# STM32H563 register map
File version: 1.6
CPU: CM33 r0p0, little endian, MPU, FPU, 4 interrupt priority bits
Registers are 32-bit, read-write, reset 0x0 unless marked. A register's access mark holds for its fields unless they carry their own. Offsets are from the block's base; [hi:lo] are bit positions; {n}, {i} and the like mark numbered series; 'fields as' and 'values as' point back to an identical list.

## RAMCFG — RAMs configuration controller
Base 0x40026000
Same registers: SEC_RAMCFG 0x50026000
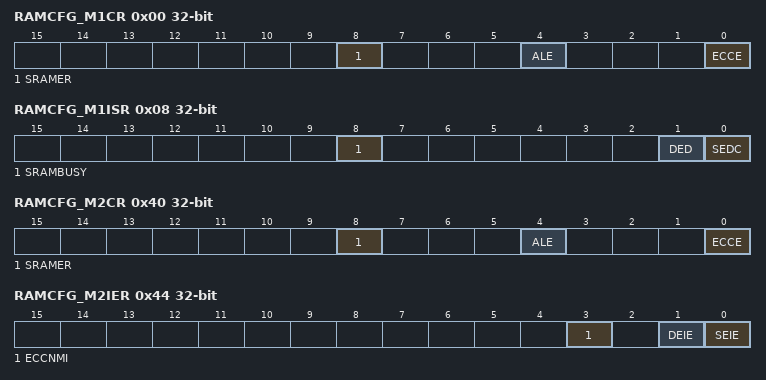
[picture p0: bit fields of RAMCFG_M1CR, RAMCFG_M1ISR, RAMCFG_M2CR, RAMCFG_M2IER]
0x00 RAMCFG_M1CR (reset mask 0xFFFFFFF0) — RAMCFG memory 1 control register
  [8] SRAMER — SRAM erase This bit can be set by software only after writing the unlock sequence in the ERASEKEY field of the RAMCFG_MxERKEYR register. Setting this bit starts the SRAM erase. This bit is automatically cleared by hardware at the end of the erase operation.
    0=No erase operation on going; 1=Erase operation on going
  [4] ALE — Address latch enable Note: This bit is reserved and must be kept at reset value in SRAM1 control register.
    0=Failing address not stored in the SRAMx ECC single/double error address registers; 1=Failing address stored in the SRAMx ECC single/double error address registers
  [0] ECCE — ECC enable. This bit reset value is defined by the user option bit configuration. When set, it can be cleared by software only after writing the unlock sequence in the RAMCFG_MxECCKEYR register. Note: This bit is reserved and must be kept at reset value in SRAM1 control register.
    0=ECC disabled; 1=ECC enabled
0x08 RAMCFG_M1ISR ro — RAMCFG memory interrupt status register
  [8] SRAMBUSY — SRAM busy with erase operation Note: Depending on the SRAM, the erase operation can be performed due to software request, system reset if the option bit is enabled, tamper detection or readout protection regression. Refer to Table 18: Internal SRAMs features.
    0=No erase operation on going; 1=Erase operation on going
  [1] DED — ECC double error detected Note: This bit is reserved and must be kept at reset value in SRAM1 interrupt status register.
    0=No double error; 1=Double error detected
  [0] SEDC — ECC single error detected and corrected Note: This bit is reserved and must be kept at reset value in SRAM1 interrupt status register.
    0=No single error; 1=Single error detected and corrected
0x28 RAMCFG_M1ERKEYR wo — RAMCFG memory 1 erase key register
  [7:0] ERASEKEY — Erase write protection key The following steps are required to unlock the write protection of the SRAMER bit in the RAMCFG_MxCR register. 1) Write 0xCA into ERASEKEY[7:0]. 2) Write 0x53 into ERASEKEY[7:0]. Note: Writing a wrong key reactivates the write protection.
0x40 RAMCFG_M2CR (reset mask 0xFFFFFFF0) — RAMCFG memory 2 control register
  fields as RAMCFG_M1CR
0x44 RAMCFG_M2IER — RAMCFG memory 2 interrupt enable register
  [3] ECCNMI — Double error NMI This bit is set by software and cleared only by a global RAMCFG reset. Note: if ECCNMI is set, the RAMCFG maskable interrupt is not generated whatever DEIE bit value.
    0=NMI not generated in case of ECC double error; 1=NMI generated in case of ECC double error
  [1] DEIE — ECC double error interrupt enable
    0=Double error interrupt disabled; 1=Double error interrupt enabled
  [0] SEIE — ECC single error interrupt enable
    0=Single error interrupt disabled; 1=Single error interrupt enabled
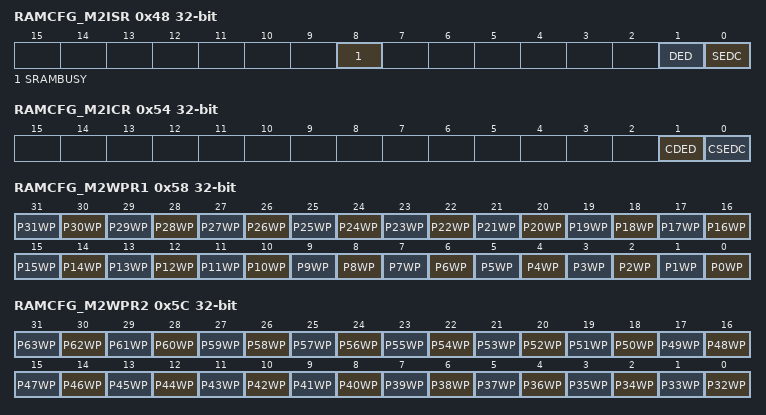
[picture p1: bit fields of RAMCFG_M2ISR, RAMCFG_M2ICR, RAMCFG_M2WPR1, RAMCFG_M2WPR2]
0x48 RAMCFG_M2ISR ro — RAMCFG memory interrupt status register
  fields as RAMCFG_M1ISR
0x4C RAMCFG_M2SEAR ro — RAMCFG memory 2 ECC single error address register
  [31:0] ESEA — ECC single error address When the ALE bit is set in the RAMCFG_MxCR register, this field is updated with the address corresponding to the ECC single error.
0x50 RAMCFG_M2DEAR ro — RAMCFG memory 2 ECC double error address register
  [31:0] EDEA — ECC double error address When the ALE bit is set in the RAMCFG_MxCR register, this field is updated with the address corresponding to the ECC double error.
0x54 RAMCFG_M2ICR — RAMCFG memory 2 interrupt clear register 2
  [1] CDED — Clear ECC double error detected Writing 1 to this flag clears the DED bit in the RAMCFG_MxISR register. Reading this flag returns the DED value.
  [0] CSEDC — Clear ECC single error detected and corrected Writing 1 to this flag clears the SEDC bit in the RAMCFG_MxISR register. Reading this flag returns the SEDC value.
0x58 RAMCFG_M2WPR1 — RAMCFG memory 2 write protection register 1
  [all] fields
    0=Write protection of SRAM2 1-Kbyte page y is disabled; 1=Write protection of SRAM2 1-Kbyte page y is enabled
  [n] P{n}WP (n=0..31) — SRAM2 1-Kbyte page y write protection These bits are set by software and cleared only by a global RAMCFG reset.
0x5C RAMCFG_M2WPR2 — RAMCFG memory 2 write protection register 2
  [all] fields
    values as the fields of RAMCFG_M2WPR1
  [n-32] P{n}WP (n=32..63) — SRAM2 1-Kbyte page y write protection These bits are set by software and cleared only by a global RAMCFG reset.
0x64 RAMCFG_M2ECCKEYR wo — RAMCFG memory 2 ECC key register
  [7:0] ECCKEY — ECC write protection key The following steps are required to unlock the write protection of the ECCE bit in the RAMCFG_MxCR register. 1) Write 0xAE into ECCKEY[7:0]. 2) Write 0x75 into ECCKEY[7:0]. Note: Writing a wrong key reactivates the write protection.
0x68 RAMCFG_M2ERKEYR wo — RAMCFG memory 2 erase key register
  fields as RAMCFG_M1ERKEYR
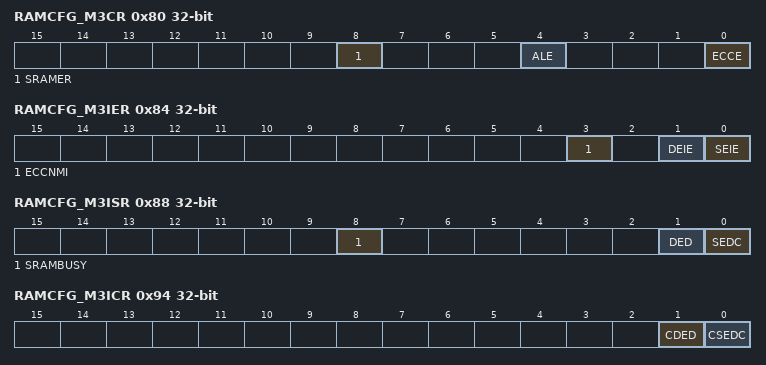
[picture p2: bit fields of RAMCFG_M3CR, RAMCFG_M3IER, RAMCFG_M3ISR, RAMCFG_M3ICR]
0x80 RAMCFG_M3CR (reset mask 0xFFFFFFF0) — RAMCFG memory 3 control register
  fields as RAMCFG_M1CR
0x84 RAMCFG_M3IER — RAMCFG memory 3 interrupt enable register
  fields as RAMCFG_M2IER
0x88 RAMCFG_M3ISR ro — RAMCFG memory interrupt status register
  fields as RAMCFG_M1ISR
0x8C RAMCFG_M3SEAR ro — RAMCFG memory 3 ECC single error address register
  fields as RAMCFG_M2SEAR
0x90 RAMCFG_M3DEAR ro — RAMCFG memory 3 ECC double error address register
  fields as RAMCFG_M2DEAR
0x94 RAMCFG_M3ICR — RAMCFG memory 3 interrupt clear register 3
  fields as RAMCFG_M2ICR
0xA4 RAMCFG_M3ECCKEYR wo — RAMCFG memory 3 ECC key register
  fields as RAMCFG_M2ECCKEYR
0xA8 RAMCFG_M3ERKEYR wo — RAMCFG memory 3 erase key register
  fields as RAMCFG_M1ERKEYR
0xE8 RAMCFG_M4ERKEYR wo — RAMCFG memory 4 erase key register
  fields as RAMCFG_M1ERKEYR
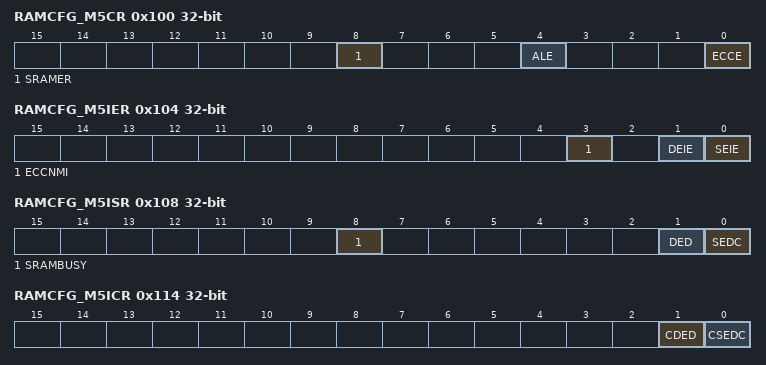
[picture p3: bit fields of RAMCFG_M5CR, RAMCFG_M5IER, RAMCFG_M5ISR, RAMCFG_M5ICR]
0x100 RAMCFG_M5CR (reset mask 0xFFFFFFF0) — RAMCFG memory 5 control register
  fields as RAMCFG_M1CR
0x104 RAMCFG_M5IER — RAMCFG memory 5 interrupt enable register
  fields as RAMCFG_M2IER
0x108 RAMCFG_M5ISR ro — RAMCFG memory interrupt status register
  fields as RAMCFG_M1ISR
0x10C RAMCFG_M5SEAR ro — RAMCFG memory 5 ECC single error address register
  fields as RAMCFG_M2SEAR
0x110 RAMCFG_M5DEAR ro — RAMCFG memory 5 ECC double error address register
  fields as RAMCFG_M2DEAR
0x114 RAMCFG_M5ICR — RAMCFG memory 5 interrupt clear register 5
  fields as RAMCFG_M2ICR
0x124 RAMCFG_M5ECCKEYR wo — RAMCFG memory 5 ECC key register
  fields as RAMCFG_M2ECCKEYR
0x128 RAMCFG_M5ERKEYR wo — RAMCFG memory 5 erase key register
  fields as RAMCFG_M1ERKEYR
